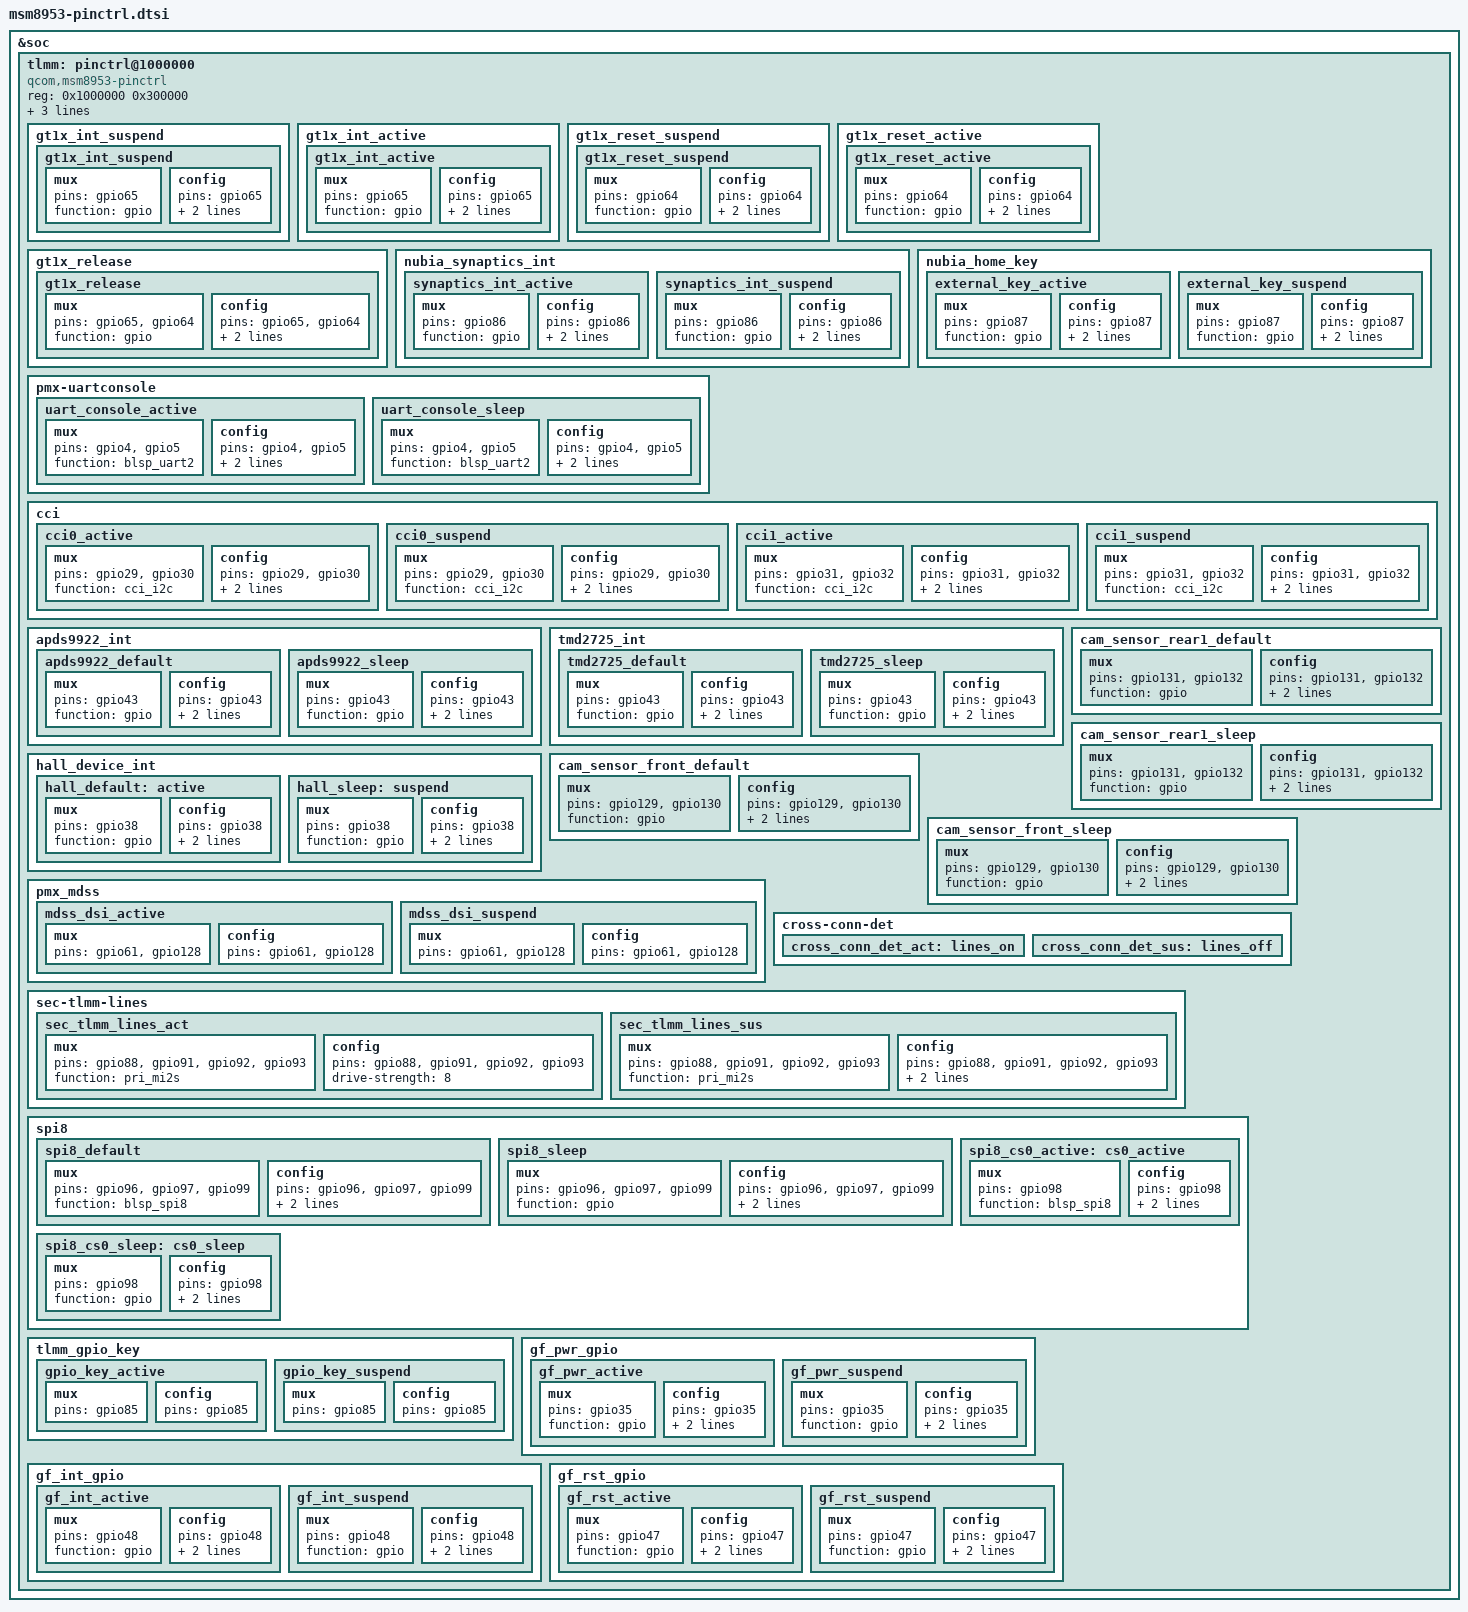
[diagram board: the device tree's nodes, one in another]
/*
 * Copyright (c) 2015-2016, The Linux Foundation. All rights reserved.
 *
 * This program is free software; you can redistribute it and/or modify
 * it under the terms of the GNU General Public License version 2 and
 * only version 2 as published by the Free Software Foundation.
 *
 * This program is distributed in the hope that it will be useful,
 * but WITHOUT ANY WARRANTY; without even the implied warranty of
 * MERCHANTABILITY or FITNESS FOR A PARTICULAR PURPOSE.  See the
 * GNU General Public License for more details.
 */

&soc {
	tlmm: pinctrl@1000000 {
		compatible = "qcom,msm8953-pinctrl";
		reg = <0x1000000 0x300000>;
		interrupts = <0 208 0>;
		gpio-controller;
		#gpio-cells = <2>;
		interrupt-controller;
		#interrupt-cells = <2>;

		gt1x_int_suspend {
			gt1x_int_suspend: gt1x_int_suspend {
				mux {
					pins = "gpio65";
					function = "gpio";
				};
				config {
					pins = "gpio65";
					drive-strength = <2>;
					bias-pull-down;
				};
			};
		};

		gt1x_int_active {
			gt1x_int_active: gt1x_int_active {
				mux {
					pins = "gpio65";
					function = "gpio";
				};
				config {
					pins = "gpio65";
					drive-strength = <8>;
					bias-disable;
				};
			};
		};


		gt1x_reset_suspend {
			gt1x_reset_suspend: gt1x_reset_suspend {
				mux {
					pins = "gpio64";
					function = "gpio";
				};
				config {
					pins = "gpio64";
					drive-strength = <2>;
					bias-pull-down;
				};
			};
		};
		gt1x_reset_active {
			gt1x_reset_active: gt1x_reset_active {
				mux {
					pins = "gpio64";
					function = "gpio";
				};
				config {
					pins = "gpio64";
					drive-strength = <8>;
					bias-pull-up;
				};
			};
		};

		gt1x_release {
			gt1x_release: gt1x_release {
				mux {
					pins = "gpio65", "gpio64";
					function = "gpio";
				};

				config {
					pins = "gpio65", "gpio64";
					drive-strength = <2>;
					bias-pull-down;
				};
			};
		};


		nubia_synaptics_int {
			synaptics_int_active: synaptics_int_active {
				mux {
					pins = "gpio86";
					function = "gpio";
				};

				config {
					pins = "gpio86";
					drive-strength = <8>;
					bias-pull-up;
				};
			};

			synaptics_int_suspend: synaptics_int_suspend {
				mux {
					pins = "gpio86";
					function = "gpio";
				};

				config {
					pins = "gpio86";
					drive-strength = <2>;
					bias-pull-up;
				};
			};
		};
		nubia_home_key {
			external_key_active: external_key_active {
				mux {
					pins = "gpio87";
					function = "gpio";
				};

				config {
					pins = "gpio87";
					drive-strength = <8>;
					bias-pull-up;
				};
			};

			external_key_suspend: external_key_suspend {
				mux {
					pins = "gpio87";
					function = "gpio";
				};

				config {
					pins = "gpio87";
					drive-strength = <2>;
					bias-pull-up;
				};
			};
		};
		
		pmx-uartconsole {
			uart_console_active: uart_console_active {
				mux {
					pins = "gpio4", "gpio5";
					function = "blsp_uart2";
				};

				config {
					pins = "gpio4", "gpio5";
					drive-strength = <2>;
					bias-disable;
				};
			};

			uart_console_sleep: uart_console_sleep {
				mux {
					pins = "gpio4", "gpio5";
					function = "blsp_uart2";
				};

				config {
					pins = "gpio4", "gpio5";
					drive-strength = <2>;
					bias-pull-down;
				};
			};

		};
		cci {
			cci0_active: cci0_active {
				/* cci0 active state */
				mux {
					/* CLK, DATA */
					pins = "gpio29", "gpio30";
					function = "cci_i2c";
				};

				config {
					pins = "gpio29", "gpio30";
					drive-strength = <2>; /* 2 MA */
					bias-disable; /* No PULL */
				};
			};

			cci0_suspend: cci0_suspend {
				/* cci0 suspended state */
				mux {
					/* CLK, DATA */
					pins = "gpio29", "gpio30";
					function = "cci_i2c";
				};

				config {
					pins = "gpio29", "gpio30";
					drive-strength = <2>; /* 2 MA */
					bias-disable; /* No PULL */
				};
			};

			cci1_active: cci1_active {
				/* cci1 active state */
				mux {
					/* CLK, DATA */
					pins = "gpio31", "gpio32";
					function = "cci_i2c";
				};

				config {
					pins = "gpio31", "gpio32";
					drive-strength = <2>; /* 2 MA */
					bias-disable; /* No PULL */
				};
			};

			cci1_suspend: cci1_suspend {
				/* cci1 suspended state */
				mux {
					/* CLK, DATA */
					pins = "gpio31", "gpio32";
					function = "cci_i2c";
				};

				config {
					pins = "gpio31", "gpio32";
					drive-strength = <2>; /* 2 MA */
					bias-disable; /* No PULL */
				};
			};
		};

		apds9922_int {
			apds9922_default: apds9922_default{
				mux {
					pins = "gpio43";
					function = "gpio";
				};
				config {
					pins = "gpio43";
					drive-strength = <6>;
					bias-pull-up;
				};
			};

			apds9922_sleep: apds9922_sleep{
				mux {
					pins = "gpio43";
					function = "gpio";
				};
				config {
					pins = "gpio43";
					drive-strength = <2>;
					bias-pull-up;
				};
			};
		};

		tmd2725_int {
			tmd2725_default: tmd2725_default{
				mux {
					pins = "gpio43";
					function = "gpio";
				};
				config {
					pins = "gpio43";
					drive-strength = <6>;
					bias-pull-up;
				};
			};
			tmd2725_sleep: tmd2725_sleep{
				mux {
					pins = "gpio43";
					function = "gpio";
				};
				config {
					pins = "gpio43";
					drive-strength = <2>;
					bias-pull-up;
				};
			};
		};
		hall_device_int{
			hall_default: active {
				mux {
					pins = "gpio38";
					function = "gpio";
				};
				config {
					pins="gpio38";
					drive-strength = <6>;
					bias-pull-up;
				};
			};

			hall_sleep: suspend {
				mux {
					pins = "gpio38";
					function = "gpio";
				};
				config{
					pins= "gpio38";
					drive-strength = <2>;
					bias-pull-up;
				};
			};
		};
		//add by nubia sensors end
		/*sensors */

		cam_sensor_rear1_default: cam_sensor_rear1_default {
			/* RESET, STANDBY */
			mux {
				pins = "gpio131","gpio132";
				function = "gpio";
			};

			config {
				pins = "gpio131","gpio132";
				bias-disable; /* No PULL */
				drive-strength = <2>; /* 2 MA */
			};
		};

		cam_sensor_rear1_sleep: cam_sensor_rear1_sleep {
			/* RESET, STANDBY */
			mux {
				pins = "gpio131","gpio132";
				function = "gpio";
			};

			config {
				pins = "gpio131","gpio132";
				bias-disable; /* No PULL */
				drive-strength = <2>; /* 2 MA */
			};
		};
		
		cam_sensor_front_default: cam_sensor_front_default {
			/* RESET, STANDBY */
			mux {
				pins = "gpio129","gpio130";
				function = "gpio";
			};

			config {
				pins = "gpio129","gpio130";
				bias-disable; /* No PULL */
				drive-strength = <2>; /* 2 MA */
			};
		};

		cam_sensor_front_sleep: cam_sensor_front_sleep {
			/* RESET, STANDBY */
			mux {
				pins = "gpio129","gpio130";
				function = "gpio";
			};

			config {
				pins = "gpio129","gpio130";
				bias-disable; /* No PULL */
				drive-strength = <2>; /* 2 MA */
			};
		};

		pmx_mdss: pmx_mdss {
			mdss_dsi_active: mdss_dsi_active {
				mux {
					pins = "gpio61", "gpio128";
				};

				config {
					pins = "gpio61", "gpio128";
				};
			};

			mdss_dsi_suspend: mdss_dsi_suspend {
				mux {
					pins = "gpio61", "gpio128";
				};

				config {
					pins = "gpio61", "gpio128";
				};
			};
			/delete-node/ mdss_dsi_gpio;
		};


		cross-conn-det {
			cross_conn_det_act: lines_on {
				/delete-node/ mux;
				/delete-node/ config;
			};

			cross_conn_det_sus: lines_off {
				/delete-node/ mux;
				/delete-node/ config;
			};
		};
/*		/delete-node/ cam_sensor_rear_sleep1;
		/delete-node/ cam_sensor_rear_vdig1;
		/delete-node/ cam_sensor_rear_vdig_sleep1;
		/delete-node/ cam_sensor_rear_default1;
		/delete-node/ blsp2_uart0_active;
		/delete-node/ blsp2_uart0_sleep; */
		/delete-node/ pmx_adv7533_int;

		sec-tlmm-lines {
			sec_tlmm_lines_act: sec_tlmm_lines_act {
				mux {
					pins = "gpio88", "gpio91", "gpio92", "gpio93";
					function = "pri_mi2s";
				};

				config {
					pins = "gpio88", "gpio91", "gpio92", "gpio93";
					drive-strength = <8>;
				};
			};

			sec_tlmm_lines_sus: sec_tlmm_lines_sus {
				mux {
					pins = "gpio88", "gpio91", "gpio92", "gpio93";
					function = "pri_mi2s";
				};

				config {
					pins = "gpio88", "gpio91", "gpio92", "gpio93";
					drive-strength = <2>;
					bias-pull-down;
				};
			};
		};


//ZTEMT: fengxun added for AL3200 ---start
		spi8 {
			spi8_default: spi8_default {
				mux {
					pins = "gpio96", "gpio97", "gpio99";
					function = "blsp_spi8";
				};

				config {
					pins = "gpio96", "gpio97", "gpio99";
					drive-strength = <12>; 
					bias-disable = <0>; 
				};
			};

			spi8_sleep: spi8_sleep {
				mux {
					pins = "gpio96", "gpio97", "gpio99";
					function = "gpio";
				};

				config {
					pins = "gpio96", "gpio97", "gpio99";
					drive-strength = <2>; 
					bias-pull-down; 
				};
			};

			spi8_cs0_active: cs0_active {
				mux {
					pins = "gpio98";
					function = "blsp_spi8";
				};

				config {
					pins = "gpio98";
					drive-strength = <2>;
					bias-disable = <0>;
				};
			};

			spi8_cs0_sleep: cs0_sleep {
				mux {
					pins = "gpio98";
					function = "gpio";
				};

				config {
					pins = "gpio98";
					drive-strength = <2>;
					bias-disable = <0>;
				};
			};
		};
//ZTEMT: fengxun added for AL3200 ---end
		tlmm_gpio_key {
			gpio_key_active: gpio_key_active {
				mux {
					pins = "gpio85";
				};

				config {
					pins = "gpio85";
				};
			};

			gpio_key_suspend: gpio_key_suspend {
				mux {
					pins = "gpio85";
				};

				config {
					pins = "gpio85";
				};
			};
		};


		/* used for spi6 and fingerprint added by nubia */
		  gf_pwr_gpio {
				gf_pwr_active: gf_pwr_active {
					mux{
						pins = "gpio35";
						function = "gpio";
					};
					config{
						pins = "gpio35";
						drive-strength = <10>;
						bias-pull-up;
					};
				};
				gf_pwr_suspend: gf_pwr_suspend {
					mux{
						pins = "gpio35";
						function = "gpio";
					};
					config{
						pins = "gpio35";
						drive-strength = <10>;
						bias-pull-up;
					};
				};
			};
			gf_int_gpio {
			gf_int_active: gf_int_active {
				mux{
					pins = "gpio48";
					function = "gpio";
				};
				config{
					pins = "gpio48";
					drive-strength = <16>;
					bias-disable;
				};
			};
			gf_int_suspend: gf_int_suspend {
				mux{
					pins = "gpio48";
					function = "gpio";
				};
				config{
					pins = "gpio48";
					drive-strength = <10>;
					bias-disable;
				};
			};
		};
		gf_rst_gpio {
			gf_rst_active: gf_rst_active {
				mux{
					pins = "gpio47";
					function = "gpio";
				};
				config{
					pins = "gpio47";
					drive-strength = <10>;
					bias-pull-up;
				};
			};
			gf_rst_suspend: gf_rst_suspend {
				mux{
					pins = "gpio47";
					function = "gpio";
				};
				config{
					pins = "gpio47";
					drive-strength = <10>;
					bias-pull-down;
				};
			};
		};
		/* used for spi5 and fingerprint added by nubia */
	};
};
